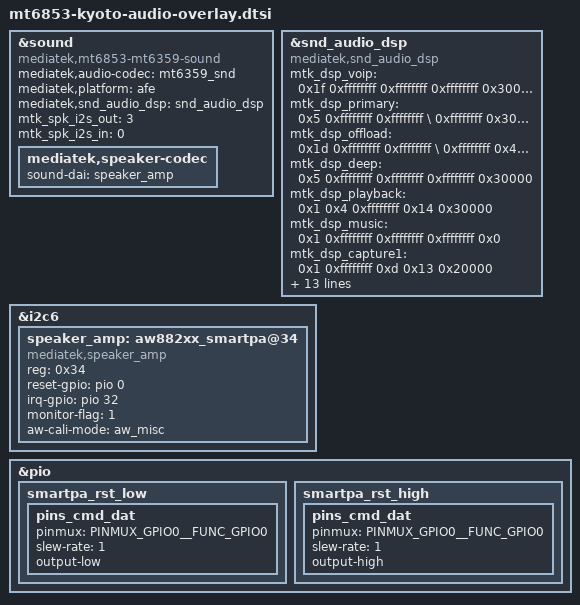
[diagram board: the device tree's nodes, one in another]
/* Copyright (c) 2020, The Linux Foundation. All rights reserved.
 *
 * This program is free software; you can redistribute it and/or modify
 * it under the terms of the GNU General Public License version 2 and
 * only version 2 as published by the Free Software Foundation.
 *
 * This program is distributed in the hope that it will be useful,
 * but WITHOUT ANY WARRANTY; without even the implied warranty of
 * MERCHANTABILITY or FITNESS FOR A PARTICULAR PURPOSE.  See the
 * GNU General Public License for more details.
 */
&sound {
	compatible = "mediatek,mt6853-mt6359-sound";
	mediatek,audio-codec = <&mt6359_snd>;
	mediatek,platform = <&afe>;
	mediatek,snd_audio_dsp = <&snd_audio_dsp>;
	mtk_spk_i2s_out = <3>;
	mtk_spk_i2s_in = <0>;
	mediatek,speaker-codec {
		sound-dai = <&speaker_amp>;
	};
};

&snd_audio_dsp {
	compatible = "mediatek,snd_audio_dsp";
	mtk_dsp_voip = <0x1f 0xffffffff 0xffffffff 0xffffffff 0x30000>;
	mtk_dsp_primary = <0x5 0xffffffff 0xffffffff \
			   0xffffffff 0x30000>;
	mtk_dsp_offload = <0x1d 0xffffffff 0xffffffff \
			   0xffffffff 0x400000>;
	mtk_dsp_deep = <0x5 0xffffffff 0xffffffff 0xffffffff 0x30000>;
	mtk_dsp_playback = <0x1 0x4 0xffffffff 0x14 0x30000>;
	mtk_dsp_music = <0x1 0xffffffff 0xffffffff 0xffffffff 0x0>;
	mtk_dsp_capture1 = <0x1 0xffffffff 0xd 0x13 0x20000>;
	mtk_dsp_a2dp = <0x0 0xffffffff 0xffffffff 0xffffffff 0x40000>;
	mtk_dsp_dataprovider = <0x0 0xffffffff 0xf 0xffffffff 0x30000>;
	mtk_dsp_call_final = <0x5 0x0 0x10 0x14 0x18000>;
	mtk_dsp_fast = <0x5 0xffffffff 0xffffffff 0xffffffff 0x5000>;
	mtk_dsp_ktv = <0x1 0x8 0x12 0xffffffff 0x10000>;
	mtk_dsp_capture_raw = <0x1 0xffffffff 0xffffffff 0xffffffff 0x20000>;
	mtk_dsp_ver = <0x1>;
	swdsp_smartpa_process_enable = <0x5>;
	mtk_dsp_mem_afe = <0x1 0x40000>; /* always enable */
};

&i2c6 {
	/* AWINIC AW882XX mono Smart PA */
	speaker_amp: aw882xx_smartpa@34 {
		compatible = "mediatek,speaker_amp";
		#sound-dai-cells = <0>;
		reg = <0x34>;
		reset-gpio = <&pio 0 0>;
		irq-gpio = <&pio 32 0x0>;
		monitor-flag = <1>;
		aw-cali-mode = "aw_misc";
		status = "okay";
	};
};

&pio {
        smartpa_rst_low: smartpa_rst_low {
                pins_cmd_dat {
                        pinmux = <PINMUX_GPIO0__FUNC_GPIO0>;
                        slew-rate = <1>;
                        output-low;
                };
        };

        smartpa_rst_high: smartpa_rst_high {
                pins_cmd_dat {
                        pinmux = <PINMUX_GPIO0__FUNC_GPIO0>;
                        slew-rate = <1>;
                        output-high;
                };
        };
};
